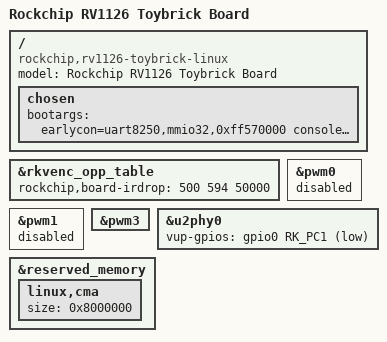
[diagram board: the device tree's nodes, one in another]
// SPDX-License-Identifier: (GPL-2.0+ OR MIT)
/*
 * Copyright (c) 2020 Rockchip Electronics Co., Ltd.
 */
/dts-v1/;
#include "rv1126.dtsi"
#include "rv1126-toybrick.dtsi"
#include "rv1126-toybrick-imx317.dtsi"
/ {
	model = "Rockchip RV1126 Toybrick Board";
	compatible = "rockchip,rv1126-toybrick-linux", "rockchip,rv1126";

	chosen {
		bootargs = "earlycon=uart8250,mmio32,0xff570000 console=ttyFIQ0 root=PARTUUID=614e0000-0000 rootfstype=ext4 rootwait snd_aloop.index=7";
	};
};

&rkvenc_opp_table {
	/*
	 * max IR-drop values on different freq condition for this board!
	 */
	rockchip,board-irdrop = <
	     /* MHz	MHz	uV */
		500	594	50000
	>;
};

&pwm0 {
    status = "disabled";
};

&pwm1 {
	status = "disabled";
};

&pwm3 {
    status = "okay";
};

&u2phy0 {
    vup-gpios = <&gpio0 RK_PC1 GPIO_ACTIVE_LOW>;
};

&reserved_memory  {
	linux,cma {
		size = <0x8000000>;
	};
};

